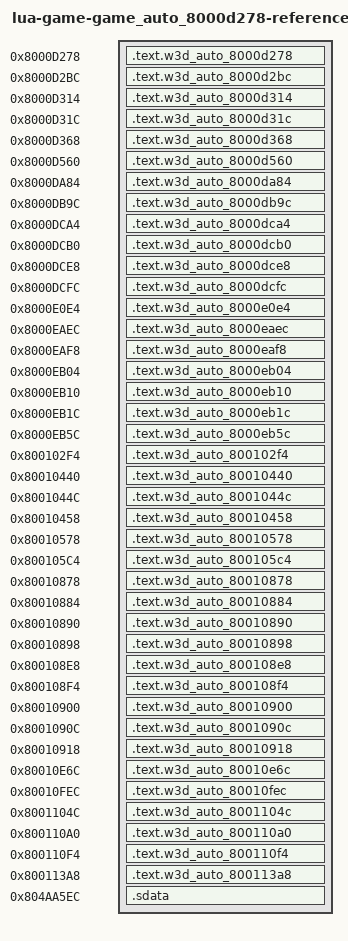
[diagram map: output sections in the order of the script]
/* Generated reference-only placements. All bodies are source-built. */
OUTPUT_FORMAT("elf32-powerpc")
OUTPUT_ARCH(powerpc)
ENTRY(w3d_auto_8000d278)
_SDA_BASE_ = 0x804b2540;
_SDA2_BASE_ = 0x804c2540;
fn_8000A7AC = 0x8000a7ac;
fn_8000A800 = 0x8000a800;
fn_8000B6BC = 0x8000b6bc;
fn_8000E0EC = 0x8000e0ec;
fn_80010630 = 0x80010630;
SECTIONS {
  .text.w3d_auto_8000d278 0x8000d278 : { *(.text.w3d_auto_8000d278) }
  .text.w3d_auto_8000d2bc 0x8000d2bc : { *(.text.w3d_auto_8000d2bc) }
  .text.w3d_auto_8000d314 0x8000d314 : { *(.text.w3d_auto_8000d314) }
  .text.w3d_auto_8000d31c 0x8000d31c : { *(.text.w3d_auto_8000d31c) }
  .text.w3d_auto_8000d368 0x8000d368 : { *(.text.w3d_auto_8000d368) }
  .text.w3d_auto_8000d560 0x8000d560 : { *(.text.w3d_auto_8000d560) }
  .text.w3d_auto_8000da84 0x8000da84 : { *(.text.w3d_auto_8000da84) }
  .text.w3d_auto_8000db9c 0x8000db9c : { *(.text.w3d_auto_8000db9c) }
  .text.w3d_auto_8000dca4 0x8000dca4 : { *(.text.w3d_auto_8000dca4) }
  .text.w3d_auto_8000dcb0 0x8000dcb0 : { *(.text.w3d_auto_8000dcb0) }
  .text.w3d_auto_8000dce8 0x8000dce8 : { *(.text.w3d_auto_8000dce8) }
  .text.w3d_auto_8000dcfc 0x8000dcfc : { *(.text.w3d_auto_8000dcfc) }
  .text.w3d_auto_8000e0e4 0x8000e0e4 : { *(.text.w3d_auto_8000e0e4) }
  .text.w3d_auto_8000eaec 0x8000eaec : { *(.text.w3d_auto_8000eaec) }
  .text.w3d_auto_8000eaf8 0x8000eaf8 : { *(.text.w3d_auto_8000eaf8) }
  .text.w3d_auto_8000eb04 0x8000eb04 : { *(.text.w3d_auto_8000eb04) }
  .text.w3d_auto_8000eb10 0x8000eb10 : { *(.text.w3d_auto_8000eb10) }
  .text.w3d_auto_8000eb1c 0x8000eb1c : { *(.text.w3d_auto_8000eb1c) }
  .text.w3d_auto_8000eb5c 0x8000eb5c : { *(.text.w3d_auto_8000eb5c) }
  .text.w3d_auto_800102f4 0x800102f4 : { *(.text.w3d_auto_800102f4) }
  .text.w3d_auto_80010440 0x80010440 : { *(.text.w3d_auto_80010440) }
  .text.w3d_auto_8001044c 0x8001044c : { *(.text.w3d_auto_8001044c) }
  .text.w3d_auto_80010458 0x80010458 : { *(.text.w3d_auto_80010458) }
  .text.w3d_auto_80010578 0x80010578 : { *(.text.w3d_auto_80010578) }
  .text.w3d_auto_800105c4 0x800105c4 : { *(.text.w3d_auto_800105c4) }
  .text.w3d_auto_80010878 0x80010878 : { *(.text.w3d_auto_80010878) }
  .text.w3d_auto_80010884 0x80010884 : { *(.text.w3d_auto_80010884) }
  .text.w3d_auto_80010890 0x80010890 : { *(.text.w3d_auto_80010890) }
  .text.w3d_auto_80010898 0x80010898 : { *(.text.w3d_auto_80010898) }
  .text.w3d_auto_800108e8 0x800108e8 : { *(.text.w3d_auto_800108e8) }
  .text.w3d_auto_800108f4 0x800108f4 : { *(.text.w3d_auto_800108f4) }
  .text.w3d_auto_80010900 0x80010900 : { *(.text.w3d_auto_80010900) }
  .text.w3d_auto_8001090c 0x8001090c : { *(.text.w3d_auto_8001090c) }
  .text.w3d_auto_80010918 0x80010918 : { *(.text.w3d_auto_80010918) }
  .text.w3d_auto_80010e6c 0x80010e6c : { *(.text.w3d_auto_80010e6c) }
  .text.w3d_auto_80010fec 0x80010fec : { *(.text.w3d_auto_80010fec) }
  .text.w3d_auto_8001104c 0x8001104c : { *(.text.w3d_auto_8001104c) }
  .text.w3d_auto_800110a0 0x800110a0 : { *(.text.w3d_auto_800110a0) }
  .text.w3d_auto_800110f4 0x800110f4 : { *(.text.w3d_auto_800110f4) }
  .text.w3d_auto_800113a8 0x800113a8 : { *(.text.w3d_auto_800113a8) }
  .sdata 0x804aa5ec (NOLOAD) : {
    . = 0x0; lbl_804AA5EC = .;
    . = 0x4; lbl_804AA5F0 = .;
    . = 0x8; lbl_804AA5F4 = .;
    . = 0xc; lbl_804AA5F8 = .;
    . = 0x10; lbl_804AA5FC = .;
    . = 0x14; lbl_804AA600 = .;
    . = 0x18; lbl_804AA604 = .;
    . = 0x1c; lbl_804AA608 = .;
    . = 0x20; lbl_804AA60C = .;
    . = 0x24; lbl_804AA610 = .;
    . = 0x28; lbl_804AA614 = .;
    . = 0x2c; lbl_804AA618 = .;
    . = 0x30; lbl_804AA61C = .;
    . = 0x34; lbl_804AA620 = .;
    . = 0x38; lbl_804AA624 = .;
    . = 0x3c; lbl_804AA628 = .;
    . = 0x40; lbl_804AA62C = .;
    . = 0x44; lbl_804AA630 = .;
    . = 0x48; lbl_804AA634 = .;
    . = 0x4c; lbl_804AA638 = .;
    . = 0x50; lbl_804AA63C = .;
    . = 0x54; lbl_804AA640 = .;
    . = 0x58; lbl_804AA644 = .;
    . = 0x5c; lbl_804AA648 = .;
    . = 0x60; lbl_804AA64C = .;
    . = 0x64; lbl_804AA650 = .;
    . = 0x68; lbl_804AA654 = .;
    . = 0x6c; lbl_804AA658 = .;
    . = 0x70; lbl_804AA65C = .;
    . = 0x74; lbl_804AA660 = .;
    . = 0x78; lbl_804AA664 = .;
    . = 0x7c; lbl_804AA668 = .;
    . = 0x80; lbl_804AA66C = .;
    . = 0x84; lbl_804AA670 = .;
    . = 0x88; lbl_804AA674 = .;
    . = 0x8c; lbl_804AA678 = .;
    . = 0xec; lbl_804AA6D8 = .;
    . += 1; }
  /DISCARD/ : { *(.text*) *(.rodata*) *(.data*) *(.bss*) *(.sdata*) *(.sbss*) *(.comment) }
}
